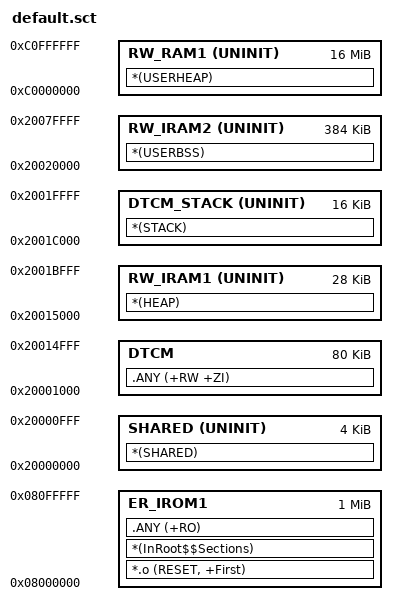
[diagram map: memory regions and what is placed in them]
; *************************************************************
; *** Scatter-Loading Description File generated by uVision ***
; *************************************************************

LR_IROM1 0x08000000 0x00100000  {    ; load region size_region
  ER_IROM1 0x08000000 0x00100000  {  ; load address = execution address
   *.o (RESET, +First)
   *(InRoot$$Sections)
   .ANY (+RO)
  }
  SHARED 0x20000000 UNINIT 0x00001000  {  ; DTCM
    *(SHARED)
  }
  DTCM 0x20001000 0x00014000  {  ; DTCM
   .ANY (+RW +ZI)
  }
; DBG ALGO NOW ON THE BOTTOM OF STACK
  DTCM_STACK 0x2001C000 UNINIT 0x00004000  {  ; DTCM
   *(STACK)
  }
  RW_IRAM1 0x20015000 UNINIT 0x00007000  {  ; RW data
   *(HEAP)
  }
  RW_IRAM2 0x20020000 UNINIT 0x00060000  {  ; DTCM
   *(USERBSS)
  }
  RW_RAM1 0xC0000000 UNINIT 0x01000000  {  ; RW data
   *(USERHEAP)
  }
}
